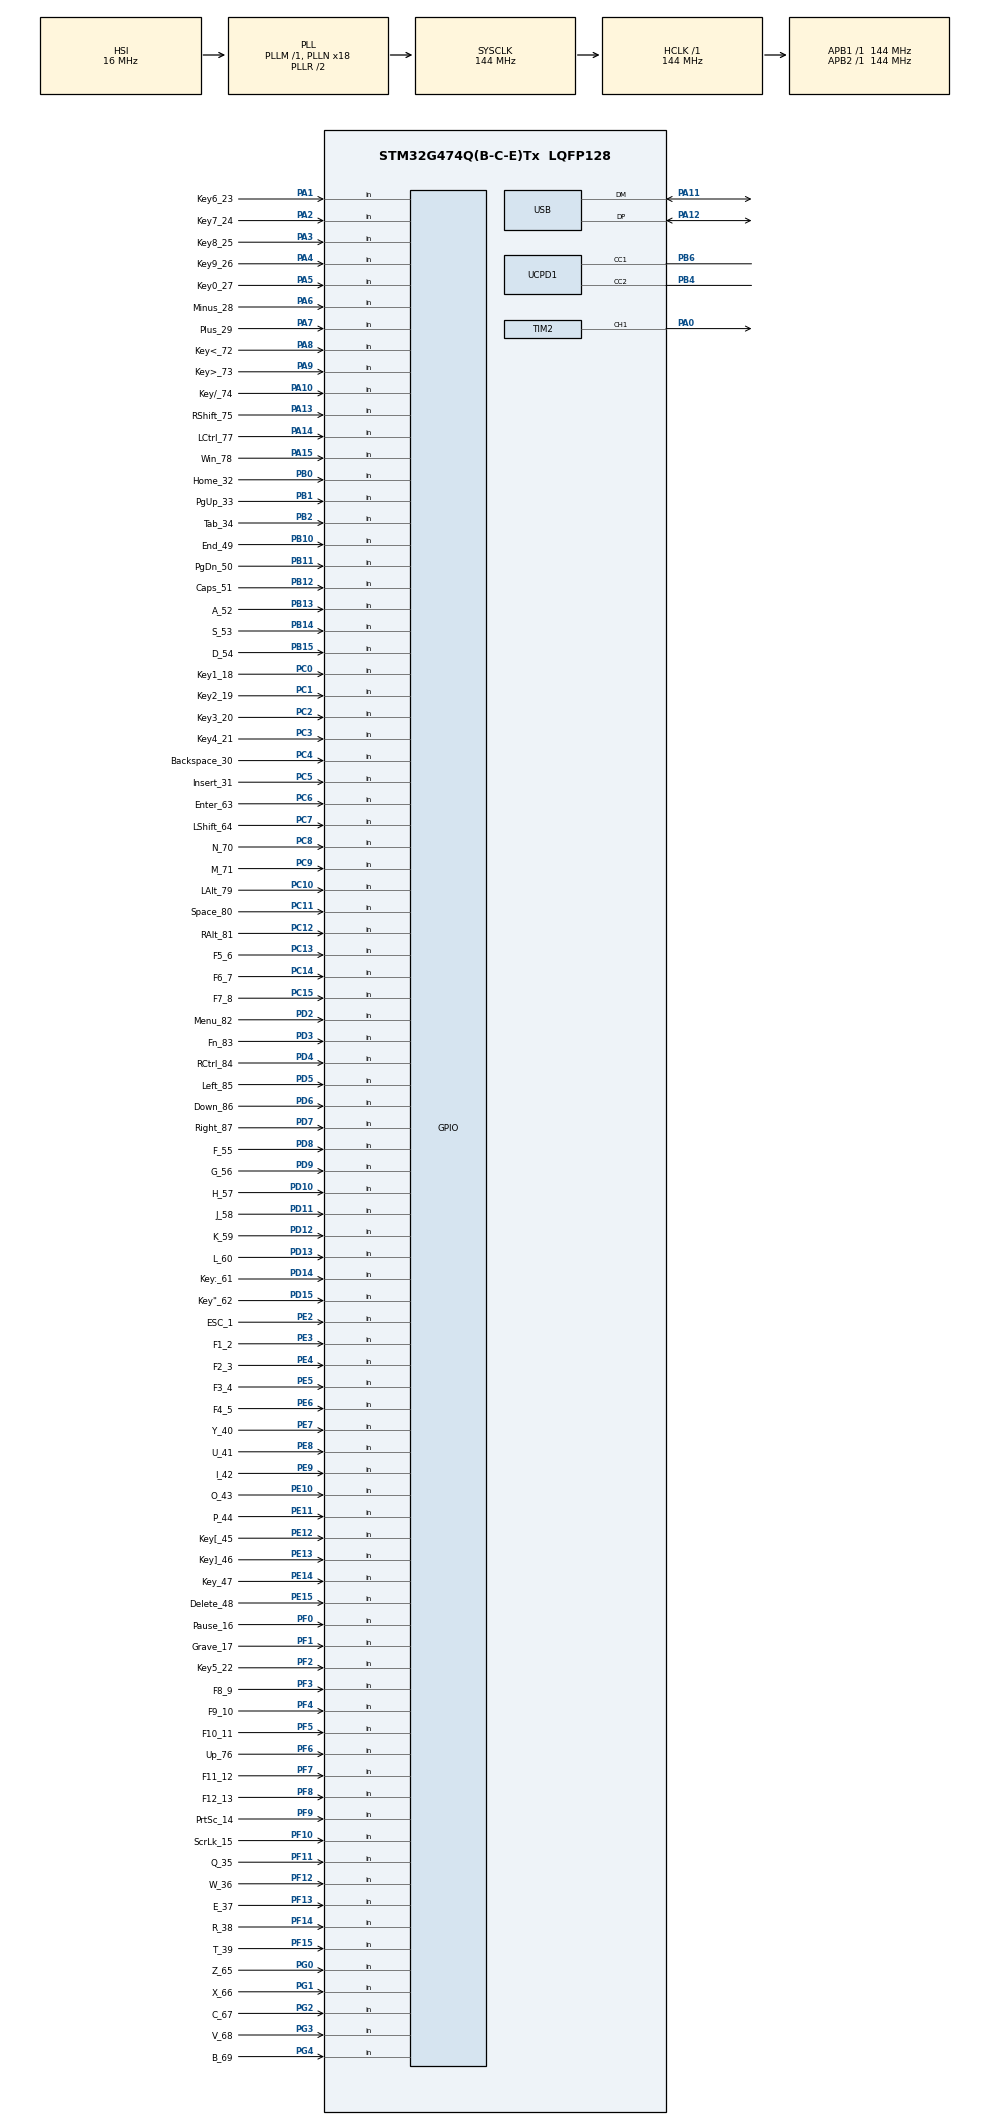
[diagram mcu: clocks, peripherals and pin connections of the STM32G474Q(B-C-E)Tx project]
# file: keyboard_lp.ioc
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Dma.Request0=TIM2_CH1
Dma.Request1=UCPD1_RX
Dma.Request2=UCPD1_TX
Dma.TIM2_CH1.0.Direction=DMA_MEMORY_TO_PERIPH
Dma.TIM2_CH1.0.EventEnable=DISABLE
Dma.TIM2_CH1.0.Instance=DMA1_Channel1
Dma.TIM2_CH1.0.MemDataAlignment=DMA_MDATAALIGN_HALFWORD
Dma.TIM2_CH1.0.MemInc=DMA_MINC_ENABLE
Dma.TIM2_CH1.0.Mode=DMA_NORMAL
Dma.TIM2_CH1.0.PeriphDataAlignment=DMA_PDATAALIGN_WORD
Dma.TIM2_CH1.0.PeriphInc=DMA_PINC_DISABLE
Dma.TIM2_CH1.0.Polarity=HAL_DMAMUX_REQ_GEN_RISING
Dma.TIM2_CH1.0.Priority=DMA_PRIORITY_VERY_HIGH
Dma.TIM2_CH1.0.RequestNumber=1
Dma.TIM2_CH1.0.SignalID=NONE
Dma.TIM2_CH1.0.SyncEnable=DISABLE
Dma.TIM2_CH1.0.SyncPolarity=HAL_DMAMUX_SYNC_NO_EVENT
Dma.TIM2_CH1.0.SyncRequestNumber=1
Dma.TIM2_CH1.0.SyncSignalID=NONE
Dma.UCPD1_RX.1.Direction=DMA_PERIPH_TO_MEMORY
Dma.UCPD1_RX.1.EventEnable=DISABLE
Dma.UCPD1_RX.1.Instance=DMA1_Channel2
Dma.UCPD1_RX.1.MemDataAlignment=DMA_MDATAALIGN_BYTE
Dma.UCPD1_RX.1.MemInc=DMA_MINC_ENABLE
Dma.UCPD1_RX.1.Mode=DMA_NORMAL
Dma.UCPD1_RX.1.PeriphDataAlignment=DMA_PDATAALIGN_BYTE
Dma.UCPD1_RX.1.PeriphInc=DMA_PINC_DISABLE
Dma.UCPD1_RX.1.Polarity=HAL_DMAMUX_REQ_GEN_RISING
Dma.UCPD1_RX.1.Priority=DMA_PRIORITY_LOW
Dma.UCPD1_RX.1.RequestNumber=1
Dma.UCPD1_RX.1.SignalID=NONE
Dma.UCPD1_RX.1.SyncEnable=DISABLE
Dma.UCPD1_RX.1.SyncPolarity=HAL_DMAMUX_SYNC_NO_EVENT
Dma.UCPD1_RX.1.SyncRequestNumber=1
Dma.UCPD1_RX.1.SyncSignalID=NONE
Dma.UCPD1_TX.2.Direction=DMA_MEMORY_TO_PERIPH
Dma.UCPD1_TX.2.EventEnable=DISABLE
Dma.UCPD1_TX.2.Instance=DMA1_Channel3
Dma.UCPD1_TX.2.MemDataAlignment=DMA_MDATAALIGN_BYTE
Dma.UCPD1_TX.2.MemInc=DMA_MINC_ENABLE
Dma.UCPD1_TX.2.Mode=DMA_NORMAL
Dma.UCPD1_TX.2.PeriphDataAlignment=DMA_PDATAALIGN_BYTE
Dma.UCPD1_TX.2.PeriphInc=DMA_PINC_DISABLE
Dma.UCPD1_TX.2.Polarity=HAL_DMAMUX_REQ_GEN_RISING
Dma.UCPD1_TX.2.Priority=DMA_PRIORITY_LOW
Dma.UCPD1_TX.2.RequestNumber=1
Dma.UCPD1_TX.2.SignalID=NONE
Dma.UCPD1_TX.2.SyncEnable=DISABLE
Dma.UCPD1_TX.2.SyncPolarity=HAL_DMAMUX_SYNC_NO_EVENT
Dma.UCPD1_TX.2.SyncRequestNumber=1
Dma.UCPD1_TX.2.SyncSignalID=NONE
Mcu.Family=STM32G4
Mcu.Name=STM32G474Q(B-C-E)Tx
Mcu.Package=LQFP128
Mcu.UserConstants=LED_PWM_ARR,179;LED_PWM_BIT_0,43;LED_PWM_BIT_1,86
NVIC.DMA1_Channel1_IRQn=true\:0\:0\:false\:false\:true\:false\:true\:true
NVIC.DMA1_Channel2_IRQn=true\:0\:0\:false\:false\:true\:false\:true\:true
NVIC.DMA1_Channel3_IRQn=true\:0\:0\:false\:false\:true\:false\:true\:true
NVIC.PriorityGroup=NVIC_PRIORITYGROUP_4
NVIC.TIM2_IRQn=true\:0\:0\:false\:false\:true\:true\:true\:true
NVIC.UCPD1_IRQn=true\:0\:0\:false\:false\:true\:true\:false\:true
NVIC.USB_LP_IRQn=true\:0\:0\:false\:false\:true\:false\:true\:true
PA0.GPIO_Speed=GPIO_SPEED_FREQ_VERY_HIGH
PA0.Signal=S_TIM2_CH1
PA1.GPIO_Label=Key6_23
PA1.GPIO_PuPd=GPIO_PULLUP
PA1.Signal=GPIO_Input
PA10.GPIO_Label=Key/_74
PA10.GPIO_PuPd=GPIO_PULLUP
PA10.Signal=GPIO_Input
PA11.Mode=Device
PA11.Signal=USB_DM
PA12.Mode=Device
PA12.Signal=USB_DP
PA13.GPIO_Label=RShift_75
PA13.GPIO_PuPd=GPIO_PULLUP
PA13.Signal=GPIO_Input
PA14.GPIO_Label=LCtrl_77
PA14.GPIO_PuPd=GPIO_PULLUP
PA14.Signal=GPIO_Input
PA15.GPIO_Label=Win_78
PA15.GPIO_PuPd=GPIO_PULLUP
PA15.Signal=GPIO_Input
PA2.GPIO_Label=Key7_24
PA2.GPIO_PuPd=GPIO_PULLUP
PA2.Signal=GPIO_Input
PA3.GPIO_Label=Key8_25
PA3.GPIO_PuPd=GPIO_PULLUP
PA3.Signal=GPIO_Input
PA4.GPIO_Label=Key9_26
PA4.GPIO_PuPd=GPIO_PULLUP
PA4.Signal=GPIO_Input
PA5.GPIO_Label=Key0_27
PA5.GPIO_PuPd=GPIO_PULLUP
PA5.Signal=GPIO_Input
PA6.GPIO_Label=Minus_28
PA6.GPIO_PuPd=GPIO_PULLUP
PA6.Signal=GPIO_Input
PA7.GPIO_Label=Plus_29
PA7.GPIO_PuPd=GPIO_PULLUP
PA7.Signal=GPIO_Input
PA8.GPIO_Label=Key<_72
PA8.GPIO_PuPd=GPIO_PULLUP
PA8.Signal=GPIO_Input
PA9.GPIO_Label=Key>_73
PA9.GPIO_PuPd=GPIO_PULLUP
PA9.Signal=GPIO_Input
PB0.GPIO_Label=Home_32
PB0.GPIO_PuPd=GPIO_PULLUP
PB0.Signal=GPIO_Input
PB1.GPIO_Label=PgUp_33
PB1.GPIO_PuPd=GPIO_PULLUP
PB1.Signal=GPIO_Input
PB10.GPIO_Label=End_49
PB10.GPIO_PuPd=GPIO_PULLUP
PB10.Signal=GPIO_Input
PB11.GPIO_Label=PgDn_50
PB11.GPIO_PuPd=GPIO_PULLUP
PB11.Signal=GPIO_Input
PB12.GPIO_Label=Caps_51
PB12.GPIO_PuPd=GPIO_PULLUP
PB12.Signal=GPIO_Input
PB13.GPIO_Label=A_52
PB13.GPIO_PuPd=GPIO_PULLUP
PB13.Signal=GPIO_Input
PB14.GPIO_Label=S_53
PB14.GPIO_PuPd=GPIO_PULLUP
PB14.Signal=GPIO_Input
PB15.GPIO_Label=D_54
PB15.GPIO_PuPd=GPIO_PULLUP
PB15.Signal=GPIO_Input
PB2.GPIO_Label=Tab_34
PB2.GPIO_PuPd=GPIO_PULLUP
PB2.Signal=GPIO_Input
PB4.Mode=Sink_AllSignals
PB4.Signal=UCPD1_CC2
PB6.Mode=Sink_AllSignals
PB6.Signal=UCPD1_CC1
PC0.GPIO_Label=Key1_18
PC0.GPIO_PuPd=GPIO_PULLUP
PC0.Signal=GPIO_Input
PC1.GPIO_Label=Key2_19
PC1.GPIO_PuPd=GPIO_PULLUP
PC1.Signal=GPIO_Input
PC10.GPIO_Label=LAlt_79
PC10.GPIO_PuPd=GPIO_PULLUP
PC10.Signal=GPIO_Input
PC11.GPIO_Label=Space_80
PC11.GPIO_PuPd=GPIO_PULLUP
PC11.Signal=GPIO_Input
PC12.GPIO_Label=RAlt_81
PC12.GPIO_PuPd=GPIO_PULLUP
PC12.Signal=GPIO_Input
PC13.GPIO_Label=F5_6
PC13.GPIO_PuPd=GPIO_PULLUP
PC13.Signal=GPIO_Input
PC14-OSC32_IN.GPIO_Label=F6_7
PC14-OSC32_IN.GPIO_PuPd=GPIO_PULLUP
PC14-OSC32_IN.Signal=GPIO_Input
PC15-OSC32_OUT.GPIO_Label=F7_8
PC15-OSC32_OUT.GPIO_PuPd=GPIO_PULLUP
PC15-OSC32_OUT.Signal=GPIO_Input
PC2.GPIO_Label=Key3_20
PC2.GPIO_PuPd=GPIO_PULLUP
PC2.Signal=GPIO_Input
PC3.GPIO_Label=Key4_21
PC3.GPIO_PuPd=GPIO_PULLUP
PC3.Signal=GPIO_Input
PC4.GPIO_Label=Backspace_30
PC4.GPIO_PuPd=GPIO_PULLUP
PC4.Signal=GPIO_Input
PC5.GPIO_Label=Insert_31
PC5.GPIO_PuPd=GPIO_PULLUP
PC5.Signal=GPIO_Input
PC6.GPIO_Label=Enter_63
PC6.GPIO_PuPd=GPIO_PULLUP
PC6.Signal=GPIO_Input
PC7.GPIO_Label=LShift_64
PC7.GPIO_PuPd=GPIO_PULLUP
PC7.Signal=GPIO_Input
PC8.GPIO_Label=N_70
PC8.GPIO_PuPd=GPIO_PULLUP
PC8.Signal=GPIO_Input
PC9.GPIO_Label=M_71
PC9.GPIO_PuPd=GPIO_PULLUP
PC9.Signal=GPIO_Input
PD10.GPIO_Label=H_57
PD10.GPIO_PuPd=GPIO_PULLUP
PD10.Signal=GPIO_Input
PD11.GPIO_Label=J_58
PD11.GPIO_PuPd=GPIO_PULLUP
PD11.Signal=GPIO_Input
PD12.GPIO_Label=K_59
PD12.GPIO_PuPd=GPIO_PULLUP
PD12.Signal=GPIO_Input
PD13.GPIO_Label=L_60
PD13.GPIO_PuPd=GPIO_PULLUP
PD13.Signal=GPIO_Input
PD14.GPIO_Label=Key\:_61
PD14.GPIO_PuPd=GPIO_PULLUP
PD14.Signal=GPIO_Input
PD15.GPIO_Label=Key"_62
PD15.GPIO_PuPd=GPIO_PULLUP
PD15.Signal=GPIO_Input
PD2.GPIO_Label=Menu_82
PD2.GPIO_PuPd=GPIO_PULLUP
PD2.Signal=GPIO_Input
PD3.GPIO_Label=Fn_83
PD3.GPIO_PuPd=GPIO_PULLUP
PD3.Signal=GPIO_Input
PD4.GPIO_Label=RCtrl_84
PD4.GPIO_PuPd=GPIO_PULLUP
PD4.Signal=GPIO_Input
PD5.GPIO_Label=Left_85
PD5.GPIO_PuPd=GPIO_PULLUP
PD5.Signal=GPIO_Input
PD6.GPIO_Label=Down_86
PD6.GPIO_PuPd=GPIO_PULLUP
PD6.Signal=GPIO_Input
PD7.GPIO_Label=Right_87
PD7.GPIO_PuPd=GPIO_PULLUP
PD7.Signal=GPIO_Input
PD8.GPIO_Label=F_55
PD8.GPIO_PuPd=GPIO_PULLUP
PD8.Signal=GPIO_Input
PD9.GPIO_Label=G_56
PD9.GPIO_PuPd=GPIO_PULLUP
PD9.Signal=GPIO_Input
PE10.GPIO_Label=O_43
PE10.GPIO_PuPd=GPIO_PULLUP
PE10.Signal=GPIO_Input
PE11.GPIO_Label=P_44
PE11.GPIO_PuPd=GPIO_PULLUP
PE11.Signal=GPIO_Input
PE12.GPIO_Label=Key[_45
PE12.GPIO_PuPd=GPIO_PULLUP
PE12.Signal=GPIO_Input
PE13.GPIO_Label=Key]_46
PE13.GPIO_PuPd=GPIO_PULLUP
PE13.Signal=GPIO_Input
PE14.GPIO_Label=Key\\_47
PE14.GPIO_PuPd=GPIO_PULLUP
PE14.Signal=GPIO_Input
PE15.GPIO_Label=Delete_48
PE15.GPIO_PuPd=GPIO_PULLUP
PE15.Signal=GPIO_Input
PE2.GPIO_Label=ESC_1
PE2.GPIO_PuPd=GPIO_PULLUP
PE2.Signal=GPIO_Input
PE3.GPIO_Label=F1_2
PE3.GPIO_PuPd=GPIO_PULLUP
PE3.Signal=GPIO_Input
PE4.GPIO_Label=F2_3
PE4.GPIO_PuPd=GPIO_PULLUP
PE4.Signal=GPIO_Input
PE5.GPIO_Label=F3_4
PE5.GPIO_PuPd=GPIO_PULLUP
PE5.Signal=GPIO_Input
PE6.GPIO_Label=F4_5
PE6.GPIO_PuPd=GPIO_PULLUP
PE6.Signal=GPIO_Input
PE7.GPIO_Label=Y_40
PE7.GPIO_PuPd=GPIO_PULLUP
PE7.Signal=GPIO_Input
PE8.GPIO_Label=U_41
PE8.GPIO_PuPd=GPIO_PULLUP
PE8.Signal=GPIO_Input
PE9.GPIO_Label=I_42
PE9.GPIO_PuPd=GPIO_PULLUP
PE9.Signal=GPIO_Input
PF0-OSC_IN.GPIO_Label=Pause_16
PF0-OSC_IN.GPIO_PuPd=GPIO_PULLUP
PF0-OSC_IN.Signal=GPIO_Input
PF1-OSC_OUT.GPIO_Label=Grave_17
PF1-OSC_OUT.GPIO_PuPd=GPIO_PULLUP
PF1-OSC_OUT.Signal=GPIO_Input
PF10.GPIO_Label=ScrLk_15
PF10.GPIO_PuPd=GPIO_PULLUP
PF10.Signal=GPIO_Input
PF11.GPIO_Label=Q_35
PF11.GPIO_PuPd=GPIO_PULLUP
PF11.Signal=GPIO_Input
PF12.GPIO_Label=W_36
PF12.GPIO_PuPd=GPIO_PULLUP
PF12.Signal=GPIO_Input
PF13.GPIO_Label=E_37
PF13.GPIO_PuPd=GPIO_PULLUP
PF13.Signal=GPIO_Input
PF14.GPIO_Label=R_38
PF14.GPIO_PuPd=GPIO_PULLUP
PF14.Signal=GPIO_Input
PF15.GPIO_Label=T_39
PF15.GPIO_PuPd=GPIO_PULLUP
PF15.Signal=GPIO_Input
PF2.GPIO_Label=Key5_22
PF2.GPIO_PuPd=GPIO_PULLUP
PF2.Signal=GPIO_Input
PF3.GPIO_Label=F8_9
PF3.GPIO_PuPd=GPIO_PULLUP
PF3.Signal=GPIO_Input
PF4.GPIO_Label=F9_10
PF4.GPIO_PuPd=GPIO_PULLUP
PF4.Signal=GPIO_Input
PF5.GPIO_Label=F10_11
PF5.GPIO_PuPd=GPIO_PULLUP
PF5.Signal=GPIO_Input
PF6.GPIO_Label=Up_76
PF6.GPIO_PuPd=GPIO_PULLUP
PF6.Signal=GPIO_Input
PF7.GPIO_Label=F11_12
PF7.GPIO_PuPd=GPIO_PULLUP
PF7.Signal=GPIO_Input
PF8.GPIO_Label=F12_13
PF8.GPIO_PuPd=GPIO_PULLUP
PF8.Signal=GPIO_Input
PF9.GPIO_Label=PrtSc_14
PF9.GPIO_PuPd=GPIO_PULLUP
PF9.Signal=GPIO_Input
PG0.GPIO_Label=Z_65
PG0.GPIO_PuPd=GPIO_PULLUP
PG0.Signal=GPIO_Input
PG1.GPIO_Label=X_66
PG1.GPIO_PuPd=GPIO_PULLUP
PG1.Signal=GPIO_Input
PG2.GPIO_Label=C_67
PG2.GPIO_PuPd=GPIO_PULLUP
PG2.Signal=GPIO_Input
PG3.GPIO_Label=V_68
PG3.GPIO_PuPd=GPIO_PULLUP
PG3.Signal=GPIO_Input
PG4.GPIO_Label=B_69
PG4.GPIO_PuPd=GPIO_PULLUP
PG4.Signal=GPIO_Input
ProjectManager.HeapSize=0x200
ProjectManager.StackSize=0x400
ProjectManager.TargetToolchain=STM32CubeIDE
RCC.ADC12Freq_Value=144000000
RCC.ADC345Freq_Value=144000000
RCC.AHBFreq_Value=144000000
RCC.APB1Freq_Value=144000000
RCC.APB1TimFreq_Value=144000000
RCC.APB2Freq_Value=144000000
RCC.APB2TimFreq_Value=144000000
RCC.CK48CLockSelection=RCC_USBCLKSOURCE_HSI48
RCC.CortexFreq_Value=144000000
RCC.EXTERNAL_CLOCK_VALUE=12288000
RCC.HCLKFreq_Value=144000000
RCC.HSE_VALUE=8000000
RCC.HSI48_VALUE=48000000
RCC.HSI_VALUE=16000000
RCC.LSE_VALUE=32768
RCC.PLLN=18
RCC.PLLQ=RCC_PLLQ_DIV6
RCC.ReloadValueType=UserValue
RCC.SYSCLKFreq_VALUE=144000000
RCC.SYSCLKSource=RCC_SYSCLKSOURCE_PLLCLK
RCC.USBFreq_Value=48000000
RCC.VCOOutputFreq_Value=288000000
SH.S_TIM2_CH1.0=TIM2_CH1,PWM Generation1 CH1
TIM2.AutoReloadPreload=TIM_AUTORELOAD_PRELOAD_ENABLE
TIM2.Channel-PWM\ Generation1\ CH1=TIM_CHANNEL_1
TIM2.PeriodNoDither=179
USBPD.PE_DataSwap_P0=USBPD_TRUE
USBPD.USBPD_PORT0_PDO_SNK_FIXED_SET_OP_CURRENT_0=3000
USB_DEVICE.CLASS_NAME_FS=HID
USB_DEVICE.HID_FS_BINTERVAL=0x1
USB_DEVICE.MANUFACTURER_STRING=emb3rcia
USB_DEVICE.PRODUCT_STRING_HID_FS=keyboard_lp
USB_DEVICE.USBD_LPM_ENABLED=0
USB_DEVICE.USBD_SELF_POWERED=0
USB_DEVICE.VirtualMode=Hid
USB_DEVICE.VirtualModeFS=Hid_FS
VP_RCC_VS_USB.Mode=USB_FS
VP_SYS_VS_DBSignals.Mode=DisableDeadBatterySignals
VP_TIM2_VS_ClockSourceINT.Mode=Internal
VP_USBPD_VS_PD3MINSNK.Mode=PD3_Min_Snk
VP_USBPD_VS_USBPD1.Mode=USBPD_P0
VP_USBPD_VS_usbpd_tim3.Mode=TIM3
VP_USB_DEVICE_VS_USB_DEVICE_HID_FS.Mode=HID_FS
board=custom

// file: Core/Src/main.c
/* USER CODE BEGIN Header */
/**
  ******************************************************************************
  * @file           : main.c
  * @brief          : Main program body
  ******************************************************************************
  * @attention
  *
  * Copyright (c) 2026 STMicroelectronics.
  * All rights reserved.
  *
  * This software is licensed under terms that can be found in the LICENSE file
  * in the root directory of this software component.
  * If no LICENSE file comes with this software, it is provided AS-IS.
  *
  ******************************************************************************
  */
/* USER CODE END Header */
#include "main.h"
#include "usbpd.h"
#include "usb_device.h"

TIM_HandleTypeDef htim2;
DMA_HandleTypeDef hdma_tim2_ch1;

void SystemClock_Config(void);
static void MX_GPIO_Init(void);
static void MX_DMA_Init(void);
static void MX_TIM2_Init(void);
static void MX_UCPD1_Init(void);

/* USER CODE BEGIN 0 */
uint8_t keyboard_report[11];
// made with **help** of Google's NotebookLM
#define NUM_LEDS 87
#define BITS_PER_LED 24
#define PWM_HI 130
#define PWM_LO 43
uint32_t led_buffer[NUM_LEDS * BITS_PER_LED]; // 87 diodes, 24 bits per diode 1 byte per color
/* USER CODE END 0 */

int main(void)
{

  /* MCU Configuration--------------------------------------------------------*/

  /* Reset of all peripherals, Initializes the Flash interface and the Systick. */
  HAL_Init();

  /* Configure the system clock */
  SystemClock_Config();

  /* Initialize all configured peripherals */
  MX_GPIO_Init();
  MX_DMA_Init();
  MX_TIM2_Init();
  MX_UCPD1_Init();
  MX_USB_Device_Init();
  /* USER CODE BEGIN 2 */
4
  /* USER CODE END 2 */

  /* USBPD initialisation ---------------------------------*/
  MX_USBPD_Init();

  /* Infinite loop */
  while (1)
  {
    USBPD_DPM_Run();

    /* USER CODE BEGIN 3 */
    //made with **help** of chatgpt cuz it is my first usb-hid project in stm32cube and not kmk
    for(int i=0; i<11; i++) keyboard_report[i] = 0;

    //check every gpio pin
    if(HAL_GPIO_ReadPin(GPIOE, ESC_1_Pin) == GPIO_PIN_RESET) keyboard_report[0] |= (1 << 0);
    if(HAL_GPIO_ReadPin(GPIOE, F1_2_Pin) == GPIO_PIN_RESET) keyboard_report[0] |= (1 << 1);
    if(HAL_GPIO_ReadPin(GPIOE, F2_3_Pin) == GPIO_PIN_RESET) keyboard_report[0] |= (1 << 2);
    if(HAL_GPIO_ReadPin(GPIOE, F3_4_Pin) == GPIO_PIN_RESET) keyboard_report[0] |= (1 << 3);
    if(HAL_GPIO_ReadPin(GPIOE, F4_5_Pin) == GPIO_PIN_RESET) keyboard_report[0] |= (1 << 4);
    if(HAL_GPIO_ReadPin(GPIOE, F5_6_Pin) == GPIO_PIN_RESET) keyboard_report[0] |= (1 << 5);
    if(HAL_GPIO_ReadPin(GPIOE, F6_7_Pin) == GPIO_PIN_RESET) keyboard_report[0] |= (1 << 6);
    if(HAL_GPIO_ReadPin(GPIOE, F7_8_Pin) == GPIO_PIN_RESET) keyboard_report[0] |= (1 << 7);
    if(HAL_GPIO_ReadPin(GPIOE, F8_9_Pin) == GPIO_PIN_RESET) keyboard_report[1] |= (1 << 0);
    if(HAL_GPIO_ReadPin(GPIOE, F9_10_Pin) == GPIO_PIN_RESET) keyboard_report[1] |= (1 << 1);
    if(HAL_GPIO_ReadPin(GPIOE, F10_11_Pin) == GPIO_PIN_RESET) keyboard_report[1] |= (1 << 2);
    if(HAL_GPIO_ReadPin(GPIOE, F11_12_Pin) == GPIO_PIN_RESET) keyboard_report[1] |= (1 << 3);
    if(HAL_GPIO_ReadPin(GPIOE, F12_13_Pin) == GPIO_PIN_RESET) keyboard_report[1] |= (1 << 4);
    if(HAL_GPIO_ReadPin(GPIOE, PrtSc_14_Pin) == GPIO_PIN_RESET) keyboard_report[1] |= (1 << 5);
    if(HAL_GPIO_ReadPin(GPIOE, ScrLk_15_Pin) == GPIO_PIN_RESET) keyboard_report[1] |= (1 << 6);
    if(HAL_GPIO_ReadPin(GPIOE, Pause_16_Pin) == GPIO_PIN_RESET) keyboard_report[1] |= (1 << 7);
    if(HAL_GPIO_ReadPin(GPIOE, Grave_17_Pin) == GPIO_PIN_RESET) keyboard_report[2] |= (1 << 0);
    if(HAL_GPIO_ReadPin(GPIOE, Key1_18_Pin) == GPIO_PIN_RESET) keyboard_report[2] |= (1 << 1);
    if(HAL_GPIO_ReadPin(GPIOE, Key2_19_Pin) == GPIO_PIN_RESET) keyboard_report[2] |= (1 << 2);
    if(HAL_GPIO_ReadPin(GPIOE, Key3_20_Pin) == GPIO_PIN_RESET) keyboard_report[2] |= (1 << 3);
    if(HAL_GPIO_ReadPin(GPIOE, Key4_21_Pin) == GPIO_PIN_RESET) keyboard_report[2] |= (1 << 4);
    if(HAL_GPIO_ReadPin(GPIOE, Key5_22_Pin) == GPIO_PIN_RESET) keyboard_report[2] |= (1 << 5);
    if(HAL_GPIO_ReadPin(GPIOE, Key6_23_Pin) == GPIO_PIN_RESET) keyboard_report[2] |= (1 << 6);
    if(HAL_GPIO_ReadPin(GPIOE, Key7_24_Pin) == GPIO_PIN_RESET) keyboard_report[2] |= (1 << 7);
    if(HAL_GPIO_ReadPin(GPIOE, Key8_25_Pin) == GPIO_PIN_RESET) keyboard_report[3] |= (1 << 0);
    if(HAL_GPIO_ReadPin(GPIOE, Key9_26_Pin) == GPIO_PIN_RESET) keyboard_report[3] |= (1 << 1);
    if(HAL_GPIO_ReadPin(GPIOE, Key0_27_Pin) == GPIO_PIN_RESET) keyboard_report[3] |= (1 << 2);
    if(HAL_GPIO_ReadPin(GPIOE, Minus_28_Pin) == GPIO_PIN_RESET) keyboard_report[3] |= (1 << 3);
    if(HAL_GPIO_ReadPin(GPIOE, Plus_29_Pin) == GPIO_PIN_RESET) keyboard_report[3] |= (1 << 4);
    if(HAL_GPIO_ReadPin(GPIOE, Backspace_30_Pin) == GPIO_PIN_RESET) keyboard_report[3] |= (1 << 5);
    if(HAL_GPIO_ReadPin(GPIOE, Insert_31_Pin) == GPIO_PIN_RESET) keyboard_report[3] |= (1 << 6);
    if(HAL_GPIO_ReadPin(GPIOE, Home_32_Pin) == GPIO_PIN_RESET) keyboard_report[3] |= (1 << 7);
    if(HAL_GPIO_ReadPin(GPIOE, PgUp_33_Pin) == GPIO_PIN_RESET) keyboard_report[4] |= (1 << 0);
    if(HAL_GPIO_ReadPin(GPIOE, Tab_34_Pin) == GPIO_PIN_RESET) keyboard_report[4] |= (1 << 1);
    if(HAL_GPIO_ReadPin(GPIOE, Q_35_Pin) == GPIO_PIN_RESET) keyboard_report[4] |= (1 << 2);
    if(HAL_GPIO_ReadPin(GPIOE, W_36_Pin) == GPIO_PIN_RESET) keyboard_report[4] |= (1 << 3);
    if(HAL_GPIO_ReadPin(GPIOE, E_37_Pin) == GPIO_PIN_RESET) keyboard_report[4] |= (1 << 4);
    if(HAL_GPIO_ReadPin(GPIOE, R_38_Pin) == GPIO_PIN_RESET) keyboard_report[4] |= (1 << 5);
    if(HAL_GPIO_ReadPin(GPIOE, T_39_Pin) == GPIO_PIN_RESET) keyboard_report[4] |= (1 << 6);
    if(HAL_GPIO_ReadPin(GPIOE, Y_40_Pin) == GPIO_PIN_RESET) keyboard_report[4] |= (1 << 7);
    if(HAL_GPIO_ReadPin(GPIOE, U_41_Pin) == GPIO_PIN_RESET) keyboard_report[5] |= (1 << 0);
    if(HAL_GPIO_ReadPin(GPIOE, I_42_Pin) == GPIO_PIN_RESET) keyboard_report[5] |= (1 << 1);
    if(HAL_GPIO_ReadPin(GPIOE, O_43_Pin) == GPIO_PIN_RESET) keyboard_report[5] |= (1 << 2);
    if(HAL_GPIO_ReadPin(GPIOE, P_44_Pin) == GPIO_PIN_RESET) keyboard_report[5] |= (1 << 3);
    if(HAL_GPIO_ReadPin(GPIOE, Key__45_Pin) == GPIO_PIN_RESET) keyboard_report[5] |= (1 << 4);
    if(HAL_GPIO_ReadPin(GPIOE, Key__46_Pin) == GPIO_PIN_RESET) keyboard_report[5] |= (1 << 5);
    if(HAL_GPIO_ReadPin(GPIOE, Key__47_Pin) == GPIO_PIN_RESET) keyboard_report[5] |= (1 << 6);
    if(HAL_GPIO_ReadPin(GPIOE, Delete_48_Pin) == GPIO_PIN_RESET) keyboard_report[5] |= (1 << 7);
    if(HAL_GPIO_ReadPin(GPIOE, End_49_Pin) == GPIO_PIN_RESET) keyboard_report[6] |= (1 << 0);
    if(HAL_GPIO_ReadPin(GPIOE, PgDn_50_Pin) == GPIO_PIN_RESET) keyboard_report[6] |= (1 << 1);
    if(HAL_GPIO_ReadPin(GPIOE, Caps_51_Pin) == GPIO_PIN_RESET) keyboard_report[6] |= (1 << 2);
    if(HAL_GPIO_ReadPin(GPIOE, A_52_Pin) == GPIO_PIN_RESET) keyboard_report[6] |= (1 << 3);
    if(HAL_GPIO_ReadPin(GPIOE, S_53_Pin) == GPIO_PIN_RESET) keyboard_report[6] |= (1 << 4);
    if(HAL_GPIO_ReadPin(GPIOE, D_54_Pin) == GPIO_PIN_RESET) keyboard_report[6] |= (1 << 5);
    if(HAL_GPIO_ReadPin(GPIOE, F_55_Pin) == GPIO_PIN_RESET) keyboard_report[6] |= (1 << 6);
    if(HAL_GPIO_ReadPin(GPIOE, G_56_Pin) == GPIO_PIN_RESET) keyboard_report[6] |= (1 << 7);
    if(HAL_GPIO_ReadPin(GPIOE, H_57_Pin) == GPIO_PIN_RESET) keyboard_report[7] |= (1 << 0);
    if(HAL_GPIO_ReadPin(GPIOE, J_58_Pin) == GPIO_PIN_RESET) keyboard_report[7] |= (1 << 1);
    if(HAL_GPIO_ReadPin(GPIOE, K_59_Pin) == GPIO_PIN_RESET) keyboard_report[7] |= (1 << 2);
    if(HAL_GPIO_ReadPin(GPIOE, L_60_Pin) == GPIO_PIN_RESET) keyboard_report[7] |= (1 << 3);
    if(HAL_GPIO_ReadPin(GPIOE, Key__61_Pin) == GPIO_PIN_RESET) keyboard_report[7] |= (1 << 4);
    if(HAL_GPIO_ReadPin(GPIOE, Key__62_Pin) == GPIO_PIN_RESET) keyboard_report[7] |= (1 << 5);
    if(HAL_GPIO_ReadPin(GPIOE, Enter_63_Pin) == GPIO_PIN_RESET) keyboard_report[7] |= (1 << 6);
    if(HAL_GPIO_ReadPin(GPIOE, LShift_64_Pin) == GPIO_PIN_RESET) keyboard_report[7] |= (1 << 7);
    if(HAL_GPIO_ReadPin(GPIOE, Z_65_Pin) == GPIO_PIN_RESET) keyboard_report[8] |= (1 << 0);
    if(HAL_GPIO_ReadPin(GPIOE, X_66_Pin) == GPIO_PIN_RESET) keyboard_report[8] |= (1 << 1);
    if(HAL_GPIO_ReadPin(GPIOE, C_67_Pin) == GPIO_PIN_RESET) keyboard_report[8] |= (1 << 2);
    if(HAL_GPIO_ReadPin(GPIOE, V_68_Pin) == GPIO_PIN_RESET) keyboard_report[8] |= (1 << 3);
    if(HAL_GPIO_ReadPin(GPIOE, B_69_Pin) == GPIO_PIN_RESET) keyboard_report[8] |= (1 << 4);
    if(HAL_GPIO_ReadPin(GPIOE, N_70_Pin) == GPIO_PIN_RESET) keyboard_report[8] |= (1 << 5);
    if(HAL_GPIO_ReadPin(GPIOE, M_71_Pin) == GPIO_PIN_RESET) keyboard_report[8] |= (1 << 6);
    if(HAL_GPIO_ReadPin(GPIOE, Key__72_Pin) == GPIO_PIN_RESET) keyboard_report[8] |= (1 << 7);
    if(HAL_GPIO_ReadPin(GPIOE, Key__73_Pin) == GPIO_PIN_RESET) keyboard_report[9] |= (1 << 0);
    if(HAL_GPIO_ReadPin(GPIOE, Key__74_Pin) == GPIO_PIN_RESET) keyboard_report[9] |= (1 << 1);
    if(HAL_GPIO_ReadPin(GPIOE, RShift_75_Pin) == GPIO_PIN_RESET) keyboard_report[9] |= (1 << 2);
    if(HAL_GPIO_ReadPin(GPIOE, Up_76_Pin) == GPIO_PIN_RESET) keyboard_report[9] |= (1 << 3);
    if(HAL_GPIO_ReadPin(GPIOE, LCtrl_77_Pin) == GPIO_PIN_RESET) keyboard_report[9] |= (1 << 4);
    if(HAL_GPIO_ReadPin(GPIOE, Win_78_Pin) == GPIO_PIN_RESET) keyboard_report[9] |= (1 << 5);
    if(HAL_GPIO_ReadPin(GPIOE, LAlt_79_Pin) == GPIO_PIN_RESET) keyboard_report[9] |= (1 << 6);
    if(HAL_GPIO_ReadPin(GPIOE, Space__80_Pin) == GPIO_PIN_RESET) keyboard_report[9] |= (1 << 7);
    if(HAL_GPIO_ReadPin(GPIOE, RAlt_81_Pin) == GPIO_PIN_RESET) keyboard_report[10] |= (1 << 0);
    if(HAL_GPIO_ReadPin(GPIOE, Menu_82_Pin) == GPIO_PIN_RESET) keyboard_report[10] |= (1 << 1);
    if(HAL_GPIO_ReadPin(GPIOE, Fn_83_Pin) == GPIO_PIN_RESET) keyboard_report[10] |= (1 << 2);
    if(HAL_GPIO_ReadPin(GPIOE, RCtrl_84_Pin) == GPIO_PIN_RESET) keyboard_report[10] |= (1 << 3);
    if(HAL_GPIO_ReadPin(GPIOE, Left_85_Pin) == GPIO_PIN_RESET) keyboard_report[10] |= (1 << 4);
    if(HAL_GPIO_ReadPin(GPIOE, Down_86_Pin) == GPIO_PIN_RESET) keyboard_report[10] |= (1 << 5);
    if(HAL_GPIO_ReadPin(GPIOE, Right_87_Pin) == GPIO_PIN_RESET) keyboard_report[10] |= (1 << 6);

    // made with **help** of chatgpt and notebooklm too, help = he explained how to do it, i made the code, verified with him if it will work, and he confirmed or said it wont and said what to fix
    uint32_t color_grb;
    for(int i = 0; i < NUM_LEDS; i++) {
    	int byte = i / 8;
    	int bit = i % 8;
    	if(keyboard_report[byte] & (1 << bit)) {
    		// key pressed -> led under it goes to red
    		color_grb = (0x00 << 16) | (0xFF << 8) | 0x00;
    	} else {
    		// other leds -> white, 70% of white as per producer words
    		color_grb = (178 << 16) | (178 << 8) | 178;
    	}

		for(int b = 0; b < BITS_PER_LED; b++) {
			if(color_grb & (1 << (23 - b))) {
				led_buffer[i * BITS_PER_LED + b] = PWM_HI;
			} else {
				led_buffer[i * BITS_PER_LED + b] = PWM_LO;
			}
		}
    }

    HAL_TIM_PWM_Start_DMA(&htim2, TIM_CHANNEL_1, led_buffer, NUM_LEDS * BITS_PER_LED);

    //send report
    USBD_HID_SendReport(&hUsbDeviceFS, keyboard_report, 11);

    //delay
    HAL_Delay(4);

  }
  /* USER CODE END 3 */
}

void SystemClock_Config(void)
{
  RCC_OscInitTypeDef RCC_OscInitStruct = {0};
  RCC_ClkInitTypeDef RCC_ClkInitStruct = {0};
  RCC_CRSInitTypeDef pInit = {0};

  /** Configure the main internal regulator output voltage
  */
  HAL_PWREx_ControlVoltageScaling(PWR_REGULATOR_VOLTAGE_SCALE1);

  /** Initializes the RCC Oscillators according to the specified parameters
  * in the RCC_OscInitTypeDef structure.
  */
  RCC_OscInitStruct.OscillatorType = RCC_OSCILLATORTYPE_HSI|RCC_OSCILLATORTYPE_HSI48;
  RCC_OscInitStruct.HSIState = RCC_HSI_ON;
  RCC_OscInitStruct.HSICalibrationValue = RCC_HSICALIBRATION_DEFAULT;
  RCC_OscInitStruct.HSI48State = RCC_HSI48_ON;
  RCC_OscInitStruct.PLL.PLLState = RCC_PLL_ON;
  RCC_OscInitStruct.PLL.PLLSource = RCC_PLLSOURCE_HSI;
  RCC_OscInitStruct.PLL.PLLM = RCC_PLLM_DIV1;
  RCC_OscInitStruct.PLL.PLLN = 18;
  RCC_OscInitStruct.PLL.PLLP = RCC_PLLP_DIV2;
  RCC_OscInitStruct.PLL.PLLQ = RCC_PLLQ_DIV6;
  RCC_OscInitStruct.PLL.PLLR = RCC_PLLR_DIV2;
  if (HAL_RCC_OscConfig(&RCC_OscInitStruct) != HAL_OK)
  {
    Error_Handler();
  }

  /** Initializes the CPU, AHB and APB buses clocks
  */
  RCC_ClkInitStruct.ClockType = RCC_CLOCKTYPE_HCLK|RCC_CLOCKTYPE_SYSCLK
                              |RCC_CLOCKTYPE_PCLK1|RCC_CLOCKTYPE_PCLK2;
  RCC_ClkInitStruct.SYSCLKSource = RCC_SYSCLKSOURCE_PLLCLK;
  RCC_ClkInitStruct.AHBCLKDivider = RCC_SYSCLK_DIV1;
  RCC_ClkInitStruct.APB1CLKDivider = RCC_HCLK_DIV1;
  RCC_ClkInitStruct.APB2CLKDivider = RCC_HCLK_DIV1;

  if (HAL_RCC_ClockConfig(&RCC_ClkInitStruct, FLASH_LATENCY_4) != HAL_OK)
  {
    Error_Handler();
  }

  /** Enable the SYSCFG APB clock
  */
  __HAL_RCC_CRS_CLK_ENABLE();

  /** Configures CRS
  */
  pInit.Prescaler = RCC_CRS_SYNC_DIV1;
  pInit.Source = RCC_CRS_SYNC_SOURCE_USB;
  pInit.Polarity = RCC_CRS_SYNC_POLARITY_RISING;
  pInit.ReloadValue = 47999;
  pInit.ErrorLimitValue = 34;
  pInit.HSI48CalibrationValue = 32;

  HAL_RCCEx_CRSConfig(&pInit);
}

static void MX_TIM2_Init(void)
{

  TIM_ClockConfigTypeDef sClockSourceConfig = {0};
  TIM_MasterConfigTypeDef sMasterConfig = {0};
  TIM_OC_InitTypeDef sConfigOC = {0};

  htim2.Instance = TIM2;
  htim2.Init.Prescaler = 0;
  htim2.Init.CounterMode = TIM_COUNTERMODE_UP;
  htim2.Init.Period = 179;
  htim2.Init.ClockDivision = TIM_CLOCKDIVISION_DIV1;
  htim2.Init.AutoReloadPreload = TIM_AUTORELOAD_PRELOAD_ENABLE;
  if (HAL_TIM_Base_Init(&htim2) != HAL_OK)
  {
    Error_Handler();
  }
  sClockSourceConfig.ClockSource = TIM_CLOCKSOURCE_INTERNAL;
  if (HAL_TIM_ConfigClockSource(&htim2, &sClockSourceConfig) != HAL_OK)
  {
    Error_Handler();
  }
  if (HAL_TIM_PWM_Init(&htim2) != HAL_OK)
  {
    Error_Handler();
  }
  sMasterConfig.MasterOutputTrigger = TIM_TRGO_RESET;
  sMasterConfig.MasterSlaveMode = TIM_MASTERSLAVEMODE_DISABLE;
  if (HAL_TIMEx_MasterConfigSynchronization(&htim2, &sMasterConfig) != HAL_OK)
  {
    Error_Handler();
  }
  sConfigOC.OCMode = TIM_OCMODE_PWM1;
  sConfigOC.Pulse = 0;
  sConfigOC.OCPolarity = TIM_OCPOLARITY_HIGH;
  sConfigOC.OCFastMode = TIM_OCFAST_DISABLE;
  if (HAL_TIM_PWM_ConfigChannel(&htim2, &sConfigOC, TIM_CHANNEL_1) != HAL_OK)
  {
    Error_Handler();
  }
  HAL_TIM_MspPostInit(&htim2);

}

static void MX_UCPD1_Init(void)
{

  LL_GPIO_InitTypeDef GPIO_InitStruct = {0};

  /* Peripheral clock enable */
  LL_APB1_GRP2_EnableClock(LL_APB1_GRP2_PERIPH_UCPD1);

  LL_AHB2_GRP1_EnableClock(LL_AHB2_GRP1_PERIPH_GPIOB);
  /**UCPD1 GPIO Configuration
  PB4   ------> UCPD1_CC2
  PB6   ------> UCPD1_CC1
  */
  GPIO_InitStruct.Pin = LL_GPIO_PIN_4;
  GPIO_InitStruct.Mode = LL_GPIO_MODE_ANALOG;
  GPIO_InitStruct.Pull = LL_GPIO_PULL_NO;
  LL_GPIO_Init(GPIOB, &GPIO_InitStruct);

  GPIO_InitStruct.Pin = LL_GPIO_PIN_6;
  GPIO_InitStruct.Mode = LL_GPIO_MODE_ANALOG;
  GPIO_InitStruct.Pull = LL_GPIO_PULL_NO;
  LL_GPIO_Init(GPIOB, &GPIO_InitStruct);

  /* UCPD1 DMA Init */

  /* UCPD1_RX Init */
  LL_DMA_SetPeriphRequest(DMA1, LL_DMA_CHANNEL_2, LL_DMAMUX_REQ_UCPD1_RX);

  LL_DMA_SetDataTransferDirection(DMA1, LL_DMA_CHANNEL_2, LL_DMA_DIRECTION_PERIPH_TO_MEMORY);

  LL_DMA_SetChannelPriorityLevel(DMA1, LL_DMA_CHANNEL_2, LL_DMA_PRIORITY_LOW);

  LL_DMA_SetMode(DMA1, LL_DMA_CHANNEL_2, LL_DMA_MODE_NORMAL);

  LL_DMA_SetPeriphIncMode(DMA1, LL_DMA_CHANNEL_2, LL_DMA_PERIPH_NOINCREMENT);

  LL_DMA_SetMemoryIncMode(DMA1, LL_DMA_CHANNEL_2, LL_DMA_MEMORY_INCREMENT);

  LL_DMA_SetPeriphSize(DMA1, LL_DMA_CHANNEL_2, LL_DMA_PDATAALIGN_BYTE);

  LL_DMA_SetMemorySize(DMA1, LL_DMA_CHANNEL_2, LL_DMA_MDATAALIGN_BYTE);

  /* UCPD1_TX Init */
  LL_DMA_SetPeriphRequest(DMA1, LL_DMA_CHANNEL_3, LL_DMAMUX_REQ_UCPD1_TX);

  LL_DMA_SetDataTransferDirection(DMA1, LL_DMA_CHANNEL_3, LL_DMA_DIRECTION_MEMORY_TO_PERIPH);

  LL_DMA_SetChannelPriorityLevel(DMA1, LL_DMA_CHANNEL_3, LL_DMA_PRIORITY_LOW);

  LL_DMA_SetMode(DMA1, LL_DMA_CHANNEL_3, LL_DMA_MODE_NORMAL);

  LL_DMA_SetPeriphIncMode(DMA1, LL_DMA_CHANNEL_3, LL_DMA_PERIPH_NOINCREMENT);

  LL_DMA_SetMemoryIncMode(DMA1, LL_DMA_CHANNEL_3, LL_DMA_MEMORY_INCREMENT);

  LL_DMA_SetPeriphSize(DMA1, LL_DMA_CHANNEL_3, LL_DMA_PDATAALIGN_BYTE);

  LL_DMA_SetMemorySize(DMA1, LL_DMA_CHANNEL_3, LL_DMA_MDATAALIGN_BYTE);

  /* UCPD1 interrupt Init */
  NVIC_SetPriority(UCPD1_IRQn, NVIC_EncodePriority(NVIC_GetPriorityGrouping(),0, 0));
  NVIC_EnableIRQ(UCPD1_IRQn);

}

static void MX_DMA_Init(void)
{

  /* DMA controller clock enable */
  __HAL_RCC_DMAMUX1_CLK_ENABLE();
  __HAL_RCC_DMA1_CLK_ENABLE();

  /* DMA interrupt init */
  /* DMA1_Channel1_IRQn interrupt configuration */
  HAL_NVIC_SetPriority(DMA1_Channel1_IRQn, 0, 0);
  HAL_NVIC_EnableIRQ(DMA1_Channel1_IRQn);
  /* DMA1_Channel2_IRQn interrupt configuration */
  NVIC_SetPriority(DMA1_Channel2_IRQn, NVIC_EncodePriority(NVIC_GetPriorityGrouping(),0, 0));
  NVIC_EnableIRQ(DMA1_Channel2_IRQn);
  /* DMA1_Channel3_IRQn interrupt configuration */
  NVIC_SetPriority(DMA1_Channel3_IRQn, NVIC_EncodePriority(NVIC_GetPriorityGrouping(),0, 0));
  NVIC_EnableIRQ(DMA1_Channel3_IRQn);

}

static void MX_GPIO_Init(void)
{
  GPIO_InitTypeDef GPIO_InitStruct = {0};

  /* GPIO Ports Clock Enable */
  __HAL_RCC_GPIOE_CLK_ENABLE();
  __HAL_RCC_GPIOC_CLK_ENABLE();
  __HAL_RCC_GPIOF_CLK_ENABLE();
  __HAL_RCC_GPIOA_CLK_ENABLE();
  __HAL_RCC_GPIOB_CLK_ENABLE();
  __HAL_RCC_GPIOD_CLK_ENABLE();
  __HAL_RCC_GPIOG_CLK_ENABLE();

  /*Configure GPIO pins : ESC_1_Pin F1_2_Pin F2_3_Pin F3_4_Pin
                           F4_5_Pin Y_40_Pin U_41_Pin I_42_Pin
                           O_43_Pin P_44_Pin Key__45_Pin Key__46_Pin
                           Key__47_Pin Delete_48_Pin */
  GPIO_InitStruct.Pin = ESC_1_Pin|F1_2_Pin|F2_3_Pin|F3_4_Pin
                          |F4_5_Pin|Y_40_Pin|U_41_Pin|I_42_Pin
                          |O_43_Pin|P_44_Pin|Key__45_Pin|Key__46_Pin
                          |Key__47_Pin|Delete_48_Pin;
  GPIO_InitStruct.Mode = GPIO_MODE_INPUT;
  GPIO_InitStruct.Pull = GPIO_PULLUP;
  HAL_GPIO_Init(GPIOE, &GPIO_InitStruct);

  /*Configure GPIO pins : F5_6_Pin F6_7_Pin F7_8_Pin Key1_18_Pin
                           Key2_19_Pin Key3_20_Pin Key4_21_Pin Backspace_30_Pin
                           Insert_31_Pin Enter_63_Pin LShift_64_Pin N_70_Pin
                           M_71_Pin LAlt_79_Pin Space_80_Pin RAlt_81_Pin */
  GPIO_InitStruct.Pin = F5_6_Pin|F6_7_Pin|F7_8_Pin|Key1_18_Pin
                          |Key2_19_Pin|Key3_20_Pin|Key4_21_Pin|Backspace_30_Pin
                          |Insert_31_Pin|Enter_63_Pin|LShift_64_Pin|N_70_Pin
                          |M_71_Pin|LAlt_79_Pin|Space_80_Pin|RAlt_81_Pin;
  GPIO_InitStruct.Mode = GPIO_MODE_INPUT;
  GPIO_InitStruct.Pull = GPIO_PULLUP;
  HAL_GPIO_Init(GPIOC, &GPIO_InitStruct);

  /*Configure GPIO pins : F8_9_Pin F9_10_Pin F10_11_Pin F11_12_Pin
                           F12_13_Pin PrtSc_14_Pin ScrLk_15_Pin Pause_16_Pin
                           Grave_17_Pin Key5_22_Pin Q_35_Pin W_36_Pin
                           E_37_Pin R_38_Pin T_39_Pin Up_76_Pin */
  GPIO_InitStruct.Pin = F8_9_Pin|F9_10_Pin|F10_11_Pin|F11_12_Pin
                          |F12_13_Pin|PrtSc_14_Pin|ScrLk_15_Pin|Pause_16_Pin
                          |Grave_17_Pin|Key5_22_Pin|Q_35_Pin|W_36_Pin
                          |E_37_Pin|R_38_Pin|T_39_Pin|Up_76_Pin;
  GPIO_InitStruct.Mode = GPIO_MODE_INPUT;
  GPIO_InitStruct.Pull = GPIO_PULLUP;
  HAL_GPIO_Init(GPIOF, &GPIO_InitStruct);

  /*Configure GPIO pins : Key6_23_Pin Key7_24_Pin Key8_25_Pin Key9_26_Pin
                           Key0_27_Pin Minus_28_Pin Plus_29_Pin Key__72_Pin
                           Key__73_Pin Key__74_Pin RShift_75_Pin LCtrl_77_Pin
                           Win_78_Pin */
  GPIO_InitStruct.Pin = Key6_23_Pin|Key7_24_Pin|Key8_25_Pin|Key9_26_Pin
                          |Key0_27_Pin|Minus_28_Pin|Plus_29_Pin|Key__72_Pin
                          |Key__73_Pin|Key__74_Pin|RShift_75_Pin|LCtrl_77_Pin
                          |Win_78_Pin;
  GPIO_InitStruct.Mode = GPIO_MODE_INPUT;
  GPIO_InitStruct.Pull = GPIO_PULLUP;
  HAL_GPIO_Init(GPIOA, &GPIO_InitStruct);

  /*Configure GPIO pins : Home_32_Pin PgUp_33_Pin Tab_34_Pin End_49_Pin
                           PgDn_50_Pin Caps_51_Pin A_52_Pin S_53_Pin
                           D_54_Pin */
  GPIO_InitStruct.Pin = Home_32_Pin|PgUp_33_Pin|Tab_34_Pin|End_49_Pin
                          |PgDn_50_Pin|Caps_51_Pin|A_52_Pin|S_53_Pin
                          |D_54_Pin;
  GPIO_InitStruct.Mode = GPIO_MODE_INPUT;
  GPIO_InitStruct.Pull = GPIO_PULLUP;
  HAL_GPIO_Init(GPIOB, &GPIO_InitStruct);

  /*Configure GPIO pins : F_55_Pin G_56_Pin H_57_Pin J_58_Pin
                           K_59_Pin L_60_Pin Key__61_Pin Key__62_Pin
                           Menu_82_Pin Fn_83_Pin RCtrl_84_Pin Left_85_Pin
                           Down_86_Pin Right_87_Pin */
  GPIO_InitStruct.Pin = F_55_Pin|G_56_Pin|H_57_Pin|J_58_Pin
                          |K_59_Pin|L_60_Pin|Key__61_Pin|Key__62_Pin
                          |Menu_82_Pin|Fn_83_Pin|RCtrl_84_Pin|Left_85_Pin
                          |Down_86_Pin|Right_87_Pin;
  GPIO_InitStruct.Mode = GPIO_MODE_INPUT;
  GPIO_InitStruct.Pull = GPIO_PULLUP;
  HAL_GPIO_Init(GPIOD, &GPIO_InitStruct);

  /*Configure GPIO pins : Z_65_Pin X_66_Pin C_67_Pin V_68_Pin
                           B_69_Pin */
  GPIO_InitStruct.Pin = Z_65_Pin|X_66_Pin|C_67_Pin|V_68_Pin
                          |B_69_Pin;
  GPIO_InitStruct.Mode = GPIO_MODE_INPUT;
  GPIO_InitStruct.Pull = GPIO_PULLUP;
  HAL_GPIO_Init(GPIOG, &GPIO_InitStruct);

}

/* USER CODE BEGIN 4 */
void HAL_TIM_PWM_PulseFinishedCallback(TIM_HandleTypeDef *htim) {
    if (htim->Instance == TIM2) {
        HAL_TIM_PWM_Stop_DMA(&htim2, TIM_CHANNEL_1);
    }
}
/* USER CODE END 4 */

void Error_Handler(void)
{
  __disable_irq();
  while (1)
  {
  }
}
